VERSION ""

NS_ :

BS_:

BU_:

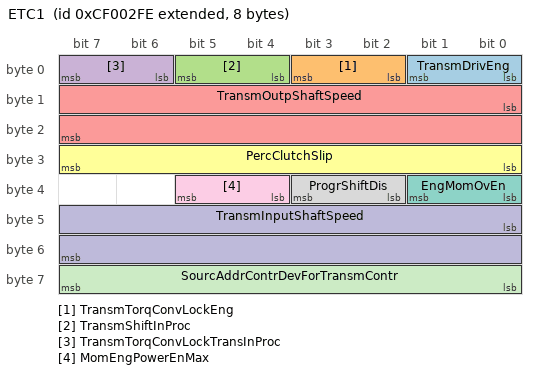
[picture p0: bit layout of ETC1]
BO_ 2364539646 ETC1: 8 Vector__XXX
 SG_ TransmDrivEng : 0|2@1+ (1,0) [0|3] "" Vector__XXX
 SG_ TransmTorqConvLockEng : 2|2@1+ (1,0) [0|3] "" Vector__XXX
 SG_ TransmShiftInProc : 4|2@1+ (1,0) [0|3] "" Vector__XXX
 SG_ TransmTorqConvLockTransInProc : 6|2@1+ (1,0) [0|3] "" Vector__XXX
 SG_ TransmOutpShaftSpeed : 8|16@1+ (0.125,0) [0|8031.875] "rpm" Vector__XXX
 SG_ PercClutchSlip : 24|8@1+ (0.4,0) [0|100] "%" Vector__XXX
 SG_ EngMomOvEn : 32|2@1+ (1,0) [0|3] "" Vector__XXX
 SG_ ProgrShiftDis : 34|2@1+ (1,0) [0|3] "" Vector__XXX
 SG_ MomEngPowerEnMax : 36|2@1+ (1,0) [0|3] "" Vector__XXX
 SG_ TransmInputShaftSpeed : 40|16@1+ (0.125,0) [0|8031.875] "rpm" Vector__XXX
 SG_ SourcAddrContrDevForTransmContr : 56|8@1+ (1,0) [0|255] "source address" Vector__XXX

CM_ BO_ 2364539646 "Electronic Transmission Controller 1";
CM_ SG_ 2364539646 TransmDrivEng "Transmission Driveline Engaged";
CM_ SG_ 2364539646 TransmTorqConvLockEng "Transmission Torque Converter Lockup Engaged";
CM_ SG_ 2364539646 TransmShiftInProc "Transmission Shift In Process";
CM_ SG_ 2364539646 TransmTorqConvLockTransInProc "Transmission Torque Converter Lockup Transition in Process";
CM_ SG_ 2364539646 TransmOutpShaftSpeed "Transmission Output Shaft Speed";
CM_ SG_ 2364539646 PercClutchSlip "Percent Clutch Slip";
CM_ SG_ 2364539646 EngMomOvEn "Engine Momentary Overspeed Enable";
CM_ SG_ 2364539646 ProgrShiftDis "Progressive Shift Disable";
CM_ SG_ 2364539646 MomEngPowerEnMax "Momentary Engine Maximum Power Enable";
CM_ SG_ 2364539646 TransmInputShaftSpeed "Transmission Input Shaft Speed";
CM_ SG_ 2364539646 SourcAddrContrDevForTransmContr "Source Address of Controlling Device for Transmission Control";
BA_DEF_ SG_  "SPN" INT 0 524287;
BA_DEF_ BO_  "VFrameFormat" ENUM  "StandardCAN","ExtendedCAN","reserved","J1939PG";
BA_DEF_  "BusType" STRING ;
BA_DEF_DEF_  "SPN" 0;
BA_DEF_DEF_  "VFrameFormat" "J1939PG";
BA_DEF_DEF_  "BusType" "CAN";
BA_ "SPN" SG_ 2364539646 TransmDrivEng 560;
BA_ "SPN" SG_ 2364539646 TransmTorqConvLockEng 573;
BA_ "SPN" SG_ 2364539646 TransmShiftInProc 574;
BA_ "SPN" SG_ 2364539646 TransmTorqConvLockTransInProc 4816;
BA_ "SPN" SG_ 2364539646 TransmOutpShaftSpeed 191;
BA_ "SPN" SG_ 2364539646 PercClutchSlip 522;
BA_ "SPN" SG_ 2364539646 EngMomOvEn 606;
BA_ "SPN" SG_ 2364539646 ProgrShiftDis 607;
BA_ "SPN" SG_ 2364539646 MomEngPowerEnMax 5015;
BA_ "SPN" SG_ 2364539646 TransmInputShaftSpeed 161;
BA_ "SPN" SG_ 2364539646 SourcAddrContrDevForTransmContr 1482;
